# CH32V203G6U6 register map
Vendor: WCH; File version: 0.1.0
CPU: QingKe V4B V4B, little endian, no MPU, no FPU, vendor SysTick, 4 interrupt priority bits
Registers are 16-bit, read-write, reset 0x0 unless marked. A register's access mark holds for its fields unless they carry their own. Offsets are from the block's base; [hi:lo] are bit positions; {n}, {i} and the like mark numbered series.

## WWDG — Window watchdog
Base 0x40002C00
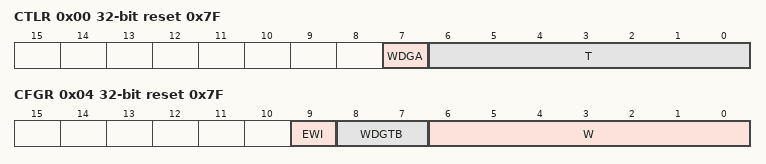
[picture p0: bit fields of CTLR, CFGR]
0x00 CTLR 32-bit reset 0x7F — Control register (WWDG_CR)
  [7] WDGA — Activation bit
  [6:0] T — 7-bit counter (MSB to LSB)
0x04 CFGR 32-bit reset 0x7F — Configuration register (WWDG_CFR)
  [9] EWI — Early Wakeup Interrupt
  [8:7] WDGTB — Timer Base
  [6:0] W — 7-bit window value
0x08 STATR 32-bit — Status register (WWDG_SR)
  [0] EWIF

## IWDG — Independent watchdog
Base 0x40003000
0x00 CTLR 32-bit — Key register (IWDG_CTLR)
  [15:0] KEY wo — Key value
0x04 PSCR 32-bit — Prescaler register (IWDG_PSCR)
  [2:0] PR — Prescaler divider
0x08 RLDR 32-bit reset 0xFFF — Reload register (IWDG_RLDR)
  [11:0] RL — Watchdog counter reload value
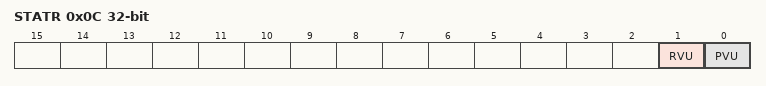
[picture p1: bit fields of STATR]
0x0C STATR 32-bit — Status register (IWDG_SR)
  [1] RVU ro — Watchdog counter reload value update
  [0] PVU ro — Watchdog prescaler value update

## USART2 — USART controller 2
Base 0x40004400
Same registers: USART1 0x40013800
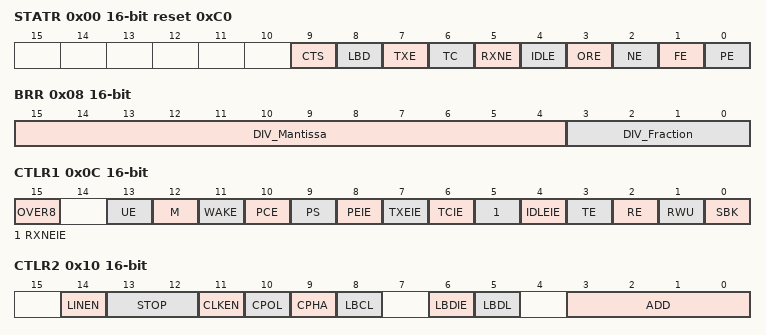
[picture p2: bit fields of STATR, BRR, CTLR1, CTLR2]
0x00 STATR reset 0xC0 — Status register
  [9] CTS — CTS flag
  [8] LBD — LIN break detection flag
  [7] TXE ro — Transmit data register empty
  [6] TC — Transmission complete
  [5] RXNE — Read data register not empty
  [4] IDLE ro — IDLE line detected
  [3] ORE ro — Overrun error
  [2] NE ro — Noise error flag
  [1] FE ro — Framing error
  [0] PE ro — Parity error
0x04 DATAR — Data register
  [8:0] DR — Data value
0x08 BRR — Baud rate register
  [15:4] DIV_Mantissa — Mantissa of USARTDIV
  [3:0] DIV_Fraction — Fraction of USARTDIV
0x0C CTLR1 — Control register 1
  [15] OVER8
  [13] UE — USART enable
  [12] M — Word length
  [11] WAKE — Wakeup method
  [10] PCE — Parity control enable
  [9] PS — Parity selection
  [8] PEIE — PE interrupt enable
  [7] TXEIE — TXE interrupt enable
  [6] TCIE — Transmission complete interrupt enable
  [5] RXNEIE — RXNE interrupt enable
  [4] IDLEIE — IDLE interrupt enable
  [3] TE — Transmitter enable
  [2] RE — Receiver enable
  [1] RWU — Receiver wakeup
  [0] SBK — Send break
0x10 CTLR2 — Control register 2
  [14] LINEN — LIN mode enable
  [13:12] STOP — STOP bits
  [11] CLKEN — Clock enable
  [10] CPOL — Clock polarity
  [9] CPHA — Clock phase
  [8] LBCL — Last bit clock pulse
  [6] LBDIE — LIN break detection interrupt enable
  [5] LBDL — lin break detection length
  [3:0] ADD — Address of the USART node
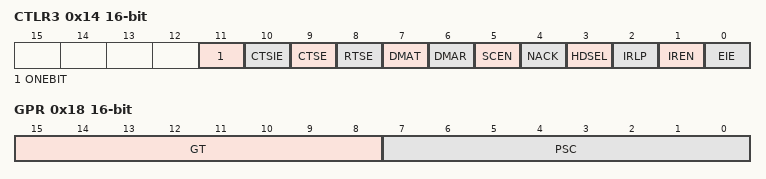
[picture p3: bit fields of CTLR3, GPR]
0x14 CTLR3 — Control register 3
  [11] ONEBIT
  [10] CTSIE — CTS interrupt enable
  [9] CTSE — CTS enable
  [8] RTSE — RTS enable
  [7] DMAT — DMA enable transmitter
  [6] DMAR — DMA enable receiver
  [5] SCEN — Smartcard mode enable
  [4] NACK — Smartcard NACK enable
  [3] HDSEL — Half-duplex selection
  [2] IRLP — IrDA low-power
  [1] IREN — IrDA mode enable
  [0] EIE — Error interrupt enable
0x18 GPR — Guard time and prescaler register
  [15:8] GT — Guard time value
  [7:0] PSC — Prescaler value

## I2C1 — I2C controller 1
Base 0x40005400
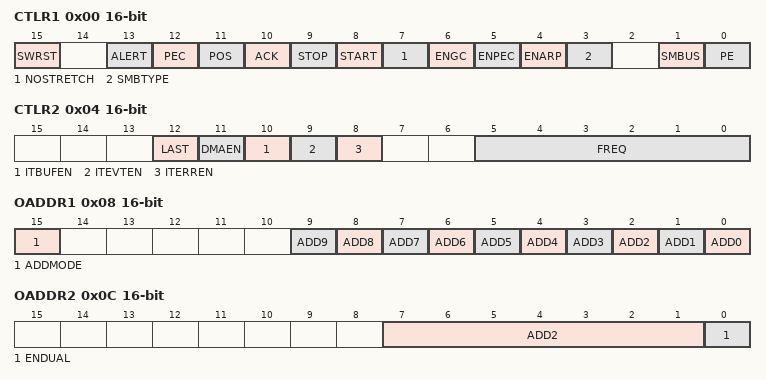
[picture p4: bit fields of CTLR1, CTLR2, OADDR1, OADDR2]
0x00 CTLR1 — Control register 1
  [15] SWRST — Software reset
  [13] ALERT — SMBus alert
  [12] PEC — Packet error checking
  [11] POS — Acknowledge/PEC Position (for data reception)
  [10] ACK — Acknowledge enable
  [9] STOP — Stop generation
  [8] START — Start generation
  [7] NOSTRETCH — Clock stretching disable (Slave mode)
  [6] ENGC — General call enable
  [5] ENPEC — PEC enable
  [4] ENARP — ARP enable
  [3] SMBTYPE — SMBus type
  [1] SMBUS — SMBus mode
  [0] PE — Peripheral enable
0x04 CTLR2 — Control register 2
  [12] LAST — DMA last transfer
  [11] DMAEN — DMA requests enable
  [10] ITBUFEN — Buffer interrupt enable
  [9] ITEVTEN — Event interrupt enable
  [8] ITERREN — Error interrupt enable
  [5:0] FREQ — Peripheral clock frequency
0x08 OADDR1 — Own address register 1
  [15] ADDMODE — Addressing mode (slave mode)
  [n] ADD{n} (n=1..9)
  [0] ADD0 — Interface address
0x0C OADDR2 — Own address register 2
  [7:1] ADD2 — Interface address
  [0] ENDUAL — Dual addressing mode enable
0x10 DATAR — Data register
  [7:0] DR_DATAR
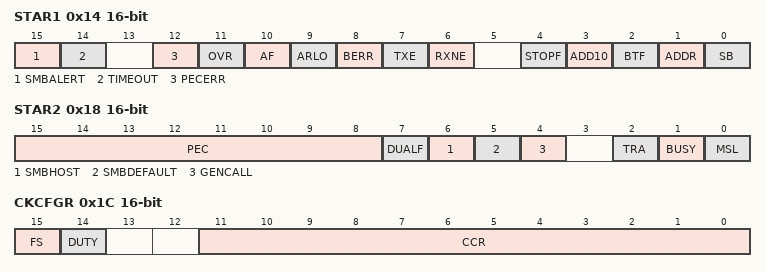
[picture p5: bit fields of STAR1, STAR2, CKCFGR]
0x14 STAR1 — Status register 1
  [15] SMBALERT — SMBus alert
  [14] TIMEOUT — Timeout or Tlow error
  [12] PECERR — PEC Error in reception
  [11] OVR — Overrun/Underrun
  [10] AF — Acknowledge failure
  [9] ARLO — Arbitration lost (master mode)
  [8] BERR — Bus error
  [7] TXE
  [6] RXNE
  [4] STOPF ro — Stop detection (slave mode)
  [3] ADD10 ro — 10-bit header sent (Master mode)
  [2] BTF ro — Byte transfer finished
  [1] ADDR ro — Address sent (master mode)/matched (slave mode)
  [0] SB ro — Start bit (Master mode)
0x18 STAR2 — Status register 2
  [15:8] PEC — acket error checking register
  [7] DUALF — Dual flag (Slave mode)
  [6] SMBHOST — SMBus host header (Slave mode)
  [5] SMBDEFAULT — SMBus device default address (Slave mode)
  [4] GENCALL — General call address (Slave mode)
  [2] TRA — Transmitter/receiver
  [1] BUSY — Bus busy
  [0] MSL — Master/slave
0x1C CKCFGR — Clock control register
  [15] FS
  [14] DUTY — Fast mode duty cycle
  [11:0] CCR — Clock control register in Fast/Standard mode (Master mode)
0x20 RTR reset 0x2 — Raise time register
  [5:0] TRISE — Maximum rise time in Fast/Standard mode (Master mode)
